AUTOSAR XML (schema 314)
package /ComponentType
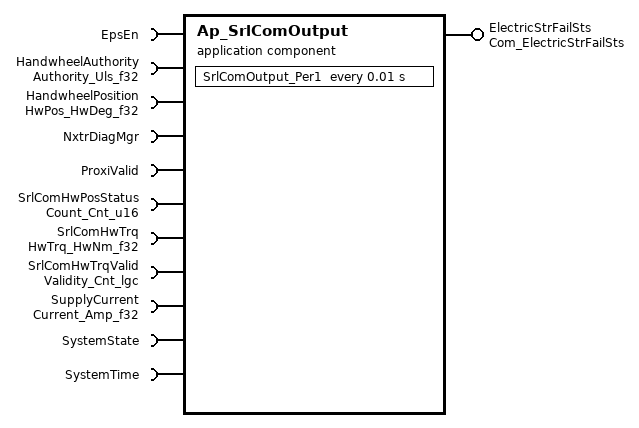
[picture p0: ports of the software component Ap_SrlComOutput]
  application software component type Ap_SrlComOutput
    provide port ElectricStrFailSts: unqueued-sender-com-spec{data-element=Cnt_lgc, can-invalidate=false, init-value=D_FALSE_CNT_LGC}, provided-interface=Com_ElectricStrFailSts
    11 x require port:
      EpsEn: client-com-spec=OP_GET, required-interface=EpsEn
      HandwheelAuthority: unqueued-receiver-com-spec{data-element=Uls_f32, init-value=D_ZERO_ULS_F32}, required-interface=Authority_Uls_f32
      HandwheelPosition: unqueued-receiver-com-spec{data-element=HwDeg_f32, init-value=D_ZERO_ULS_F32}, required-interface=HwPos_HwDeg_f32
      NxtrDiagMgr: required-com-specs=[GetNTCActive, GetNTCFailed, GetNTCStatus, SetNTCStatus], required-interface=NxtrDiagMgr
      ProxiValid: unqueued-receiver-com-spec{data-element=Cnt_lgc, init-value=D_PROXIVALID}, required-interface=ProxiValid
      SrlComHwPosStatus: unqueued-receiver-com-spec{data-element=Cnt_u16, init-value=D_ZERO_CNT_U16}, required-interface=Count_Cnt_u16
      SrlComHwTrq: unqueued-receiver-com-spec{data-element=HwNm_f32, init-value=D_ZERO_ULS_F32}, required-interface=HwTrq_HwNm_f32
      SrlComHwTrqValid: unqueued-receiver-com-spec{data-element=Cnt_lgc, init-value=D_FALSE_CNT_LGC}, required-interface=Validity_Cnt_lgc
      SupplyCurrent: unqueued-receiver-com-spec{data-element=Amp_f32, init-value=D_ZERO_ULS_F32}, required-interface=Current_Amp_f32
      SystemState: required-interface=SystemState
      SystemTime: required-interface=SystemTime
        required-com-specs:
          DtrmnElapsedTime_mS_u16
          DtrmnElapsedTime_mS_u32
          DtrmnElapsedTime_uS_u16
          DtrmnElapsedTime_uS_u32
          GetSystemTime_mS_u32
          GetSystemTime_uS_u32
  internal behavior Ap_SrlComOutput_InternalBehavior: component=Ap_SrlComOutput
    timing event TMT_SrlComOutput_Per1: mode-dependency=dependent-on-mode=SystemState.Mode.OFF, start-on-event=SrlComOutput_Per1, period=0.01
    port-api-options:
      enable-take-address=false, indirect-api=false, port=ElectricStrFailSts
      enable-take-address=false, indirect-api=false, port=EpsEn
      enable-take-address=false, indirect-api=false, port=HandwheelAuthority
      enable-take-address=false, indirect-api=false, port=HandwheelPosition
      enable-take-address=false, indirect-api=false, port=NxtrDiagMgr
      enable-take-address=false, indirect-api=false, port=ProxiValid
      enable-take-address=false, indirect-api=false, port=SrlComHwPosStatus
      enable-take-address=false, indirect-api=false, port=SrlComHwTrq
      enable-take-address=false, indirect-api=false, port=SrlComHwTrqValid
      enable-take-address=false, indirect-api=false, port=SupplyCurrent
      enable-take-address=false, indirect-api=false, port=SystemState
      enable-take-address=false, indirect-api=false, port=SystemTime
    runnable SrlComOutput_Per1
      7 x data read access:
        READ_HandwheelAuthority_Uls_f32: data-element=HandwheelAuthority.Uls_f32
        READ_HandwheelPosition_HwDeg_f32: data-element=HandwheelPosition.HwDeg_f32
        READ_ProxiValid_Cnt_lgc: data-element=ProxiValid.Cnt_lgc
        READ_SrlComHwPosStatus_Cnt_u16: data-element=SrlComHwPosStatus.Cnt_u16
        READ_SrlComHwTrq_HwNm_f32: data-element=SrlComHwTrq.HwNm_f32
        READ_SrlComHwTrqValid_Cnt_lgc: data-element=SrlComHwTrqValid.Cnt_lgc
        READ_SupplyCurrent_Amp_f32: data-element=SupplyCurrent.Amp_f32
      data write access WRITE_ElectricStrFailSts_Cnt_lgc: data-element=ElectricStrFailSts.Cnt_lgc
      5 x sync call, all with timeout=0:
        SC_EpsEn_OP_GET: operation=EpsEn.OP_GET
        SC_NxtrDiagMgr_GetNTCFailed: operation=NxtrDiagMgr.GetNTCFailed
        SC_NxtrDiagMgr_GetNTCStatus: operation=NxtrDiagMgr.GetNTCStatus
        SC_SystemTime_DtrmnElapsedTime_mS_u16: operation=SystemTime.DtrmnElapsedTime_mS_u16
        SC_SystemTime_GetSystemTime_mS_u32: operation=SystemTime.GetSystemTime_mS_u32
  swc implementation Ap_SrlComOutput_Implementation: behavior=Ap_SrlComOutput_InternalBehavior
    code-descriptors:
      code Code: type=SRC
